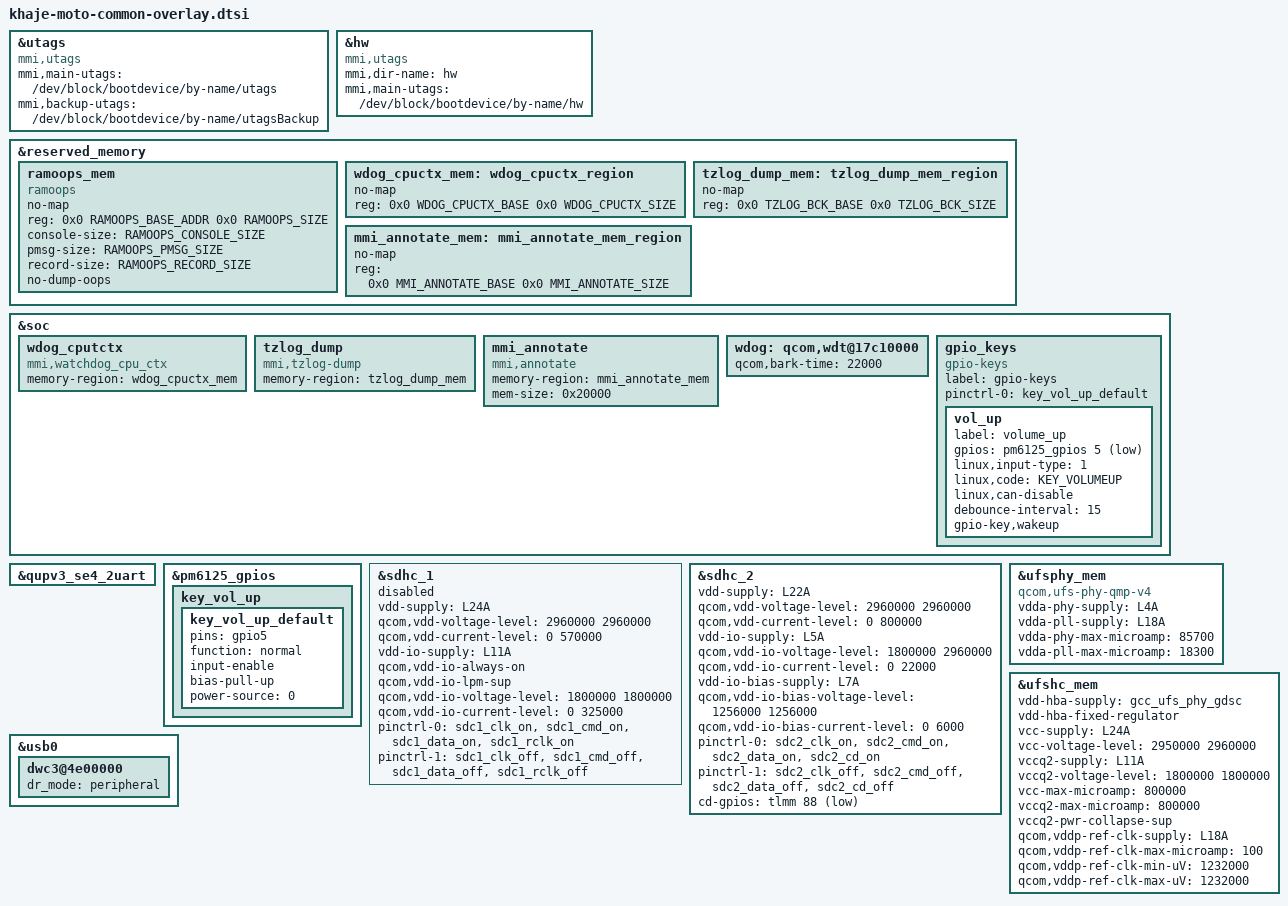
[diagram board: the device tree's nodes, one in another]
/* Copyright (c) 2020, The Linux Foundation. All rights reserved.
 *
 * This program is free software; you can redistribute it and/or modify
 * it under the terms of the GNU General Public License version 2 and
 * only version 2 as published by the Free Software Foundation.
 *
 * This program is distributed in the hope that it will be useful,
 * but WITHOUT ANY WARRANTY; without even the implied warranty of
 * MERCHANTABILITY or FITNESS FOR A PARTICULAR PURPOSE.  See the
 * GNU General Public License for more details.
 */

#include <dt-bindings/gpio/gpio.h>
#include <dt-bindings/input/input.h>
#include "carrier-channel-ids.dtsi"
#include <dt-bindings/moto/moto-mem-reserve.h>
#include "bengal-audio-overlay.dtsi"
#include "bengal-thermal-overlay.dtsi"
#include "khaje-sde-display.dtsi"

&utags {
	compatible = "mmi,utags";
	mmi,main-utags = "/dev/block/bootdevice/by-name/utags";
	mmi,backup-utags = "/dev/block/bootdevice/by-name/utagsBackup";
};

&hw {
	compatible = "mmi,utags";
	mmi,dir-name = "hw";
	mmi,main-utags = "/dev/block/bootdevice/by-name/hw";
};


&reserved_memory {
	ramoops_mem {
		compatible = "ramoops";
		no-map;
		reg = <0x0 RAMOOPS_BASE_ADDR 0x0 RAMOOPS_SIZE>;
		console-size = <RAMOOPS_CONSOLE_SIZE>;
		pmsg-size = <RAMOOPS_PMSG_SIZE>;
		record-size = <RAMOOPS_RECORD_SIZE>;
		no-dump-oops;
	};

	wdog_cpuctx_mem: wdog_cpuctx_region {
		no-map;
		reg = <0x0 WDOG_CPUCTX_BASE
			0x0 WDOG_CPUCTX_SIZE>;
	};

	tzlog_dump_mem: tzlog_dump_mem_region {
		no-map;
		reg = <0x0  TZLOG_BCK_BASE
			0x0 TZLOG_BCK_SIZE>;
	};

	mmi_annotate_mem: mmi_annotate_mem_region {
		no-map;
		reg = <0x0  MMI_ANNOTATE_BASE
			0x0 MMI_ANNOTATE_SIZE>;
	};
};

&soc {
	wdog_cputctx {
		compatible = "mmi,watchdog_cpu_ctx";
		memory-region = <&wdog_cpuctx_mem>;
	};

	tzlog_dump {
		compatible = "mmi,tzlog-dump";
		memory-region = <&tzlog_dump_mem>;
	};

	mmi_annotate {
		compatible = "mmi,annotate";
		memory-region = <&mmi_annotate_mem>;
		mem-size = <0x20000>;
	};

	wdog: qcom,wdt@17c10000 {
		qcom,bark-time = <22000>;
	};
};


&qupv3_se4_2uart {
	status = "ok";
};

&pm6125_gpios {

	key_vol_up {
		key_vol_up_default: key_vol_up_default {
			pins = "gpio5";
			function = "normal";
			input-enable;
			bias-pull-up;
			power-source = <0>;
		};
	};
};

&soc {
	gpio_keys {
		compatible = "gpio-keys";
		label = "gpio-keys";

		pinctrl-names = "default";
		pinctrl-0 = <&key_vol_up_default>;

		vol_up {
			label = "volume_up";
			gpios = <&pm6125_gpios 5 GPIO_ACTIVE_LOW>;
			linux,input-type = <1>;
			linux,code = <KEY_VOLUMEUP>;
			linux,can-disable;
			debounce-interval = <15>;
			gpio-key,wakeup;
		};
	};

};



&sdhc_1 {
	vdd-supply = <&L24A>;
	qcom,vdd-voltage-level = <2960000 2960000>;
	qcom,vdd-current-level = <0 570000>;

	vdd-io-supply = <&L11A>;
	qcom,vdd-io-always-on;
	qcom,vdd-io-lpm-sup;
	qcom,vdd-io-voltage-level = <1800000 1800000>;
	qcom,vdd-io-current-level = <0 325000>;

	pinctrl-names = "active", "sleep";
	pinctrl-0 = <&sdc1_clk_on &sdc1_cmd_on &sdc1_data_on
					&sdc1_rclk_on>;
	pinctrl-1 = <&sdc1_clk_off &sdc1_cmd_off &sdc1_data_off
					&sdc1_rclk_off>;

	status = "disabled";
};

&sdhc_2 {
	vdd-supply = <&L22A>;
	qcom,vdd-voltage-level = <2960000 2960000>;
	qcom,vdd-current-level = <0 800000>;

	vdd-io-supply = <&L5A>;
	qcom,vdd-io-voltage-level = <1800000 2960000>;
	qcom,vdd-io-current-level = <0 22000>;

	vdd-io-bias-supply = <&L7A>;
	qcom,vdd-io-bias-voltage-level = <1256000 1256000>;
	qcom,vdd-io-bias-current-level = <0 6000>;

	pinctrl-names = "active", "sleep";
	pinctrl-0 = <&sdc2_clk_on  &sdc2_cmd_on &sdc2_data_on &sdc2_cd_on>;
	pinctrl-1 = <&sdc2_clk_off &sdc2_cmd_off &sdc2_data_off &sdc2_cd_off>;

	cd-gpios = <&tlmm 88 GPIO_ACTIVE_LOW>;

	status = "ok";
};

&ufsphy_mem {
	compatible = "qcom,ufs-phy-qmp-v4";

	vdda-phy-supply = <&L4A>; /* 0.9v */
	vdda-pll-supply = <&L18A>; /* 1.8v */
	vdda-phy-max-microamp = <85700>;
	vdda-pll-max-microamp = <18300>;

	status = "ok";
};

&ufshc_mem {
	vdd-hba-supply = <&gcc_ufs_phy_gdsc>;
	vdd-hba-fixed-regulator;
	vcc-supply = <&L24A>;
	vcc-voltage-level = <2950000 2960000>;
	vccq2-supply = <&L11A>;
	vccq2-voltage-level = <1800000 1800000>;
	vcc-max-microamp = <800000>;
	vccq2-max-microamp = <800000>;
	vccq2-pwr-collapse-sup;

	qcom,vddp-ref-clk-supply = <&L18A>;
	qcom,vddp-ref-clk-max-microamp = <100>;
	qcom,vddp-ref-clk-min-uV = <1232000>;
	qcom,vddp-ref-clk-max-uV = <1232000>;

	status = "ok";
};

&usb0 {
	dwc3@4e00000 {
		dr_mode = "peripheral";
	};
};
